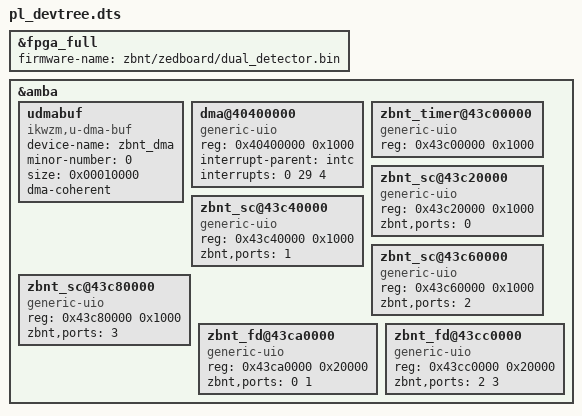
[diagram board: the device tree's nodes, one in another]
/*
	This Source Code Form is subject to the terms of the Mozilla Public
	License, v. 2.0. If a copy of the MPL was not distributed with this
	file, You can obtain one at https://mozilla.org/MPL/2.0/.
*/

/dts-v1/;
/plugin/;

/ {
	fragment@0 {
		target = <&fpga_full>;

		__overlay__ {
			firmware-name = "zbnt/zedboard/dual_detector.bin";
		};
	};

	fragment@1 {
		target = <&amba>;

		__overlay__ {
			#address-cells = <1>;
			#size-cells = <1>;

			udmabuf {
				compatible = "ikwzm,u-dma-buf";
				device-name = "zbnt_dma";
				minor-number = <0>;
				size = <0x00010000>;
				dma-coherent;
			};

			dma@40400000 {
				compatible = "generic-uio";
				reg = <0x40400000 0x1000>;

				interrupt-names = "s2mm_introut";
				interrupt-parent = <&intc>;
				interrupts = <0 29 4>;
			};

			zbnt_timer@43c00000 {
				compatible = "generic-uio";
				reg = <0x43c00000 0x1000>;
			};

			zbnt_sc@43c20000 {
				compatible = "generic-uio";
				reg = <0x43c20000 0x1000>;
				zbnt,ports = <0>;
			};

			zbnt_sc@43c40000 {
				compatible = "generic-uio";
				reg = <0x43c40000 0x1000>;
				zbnt,ports = <1>;
			};

			zbnt_sc@43c60000 {
				compatible = "generic-uio";
				reg = <0x43c60000 0x1000>;
				zbnt,ports = <2>;
			};

			zbnt_sc@43c80000 {
				compatible = "generic-uio";
				reg = <0x43c80000 0x1000>;
				zbnt,ports = <3>;
			};

			zbnt_fd@43ca0000 {
				compatible = "generic-uio";
				reg = <0x43ca0000 0x20000>;
				zbnt,ports = <0 1>;
			};

			zbnt_fd@43cc0000 {
				compatible = "generic-uio";
				reg = <0x43cc0000 0x20000>;
				zbnt,ports = <2 3>;
			};
		};
	};
};
